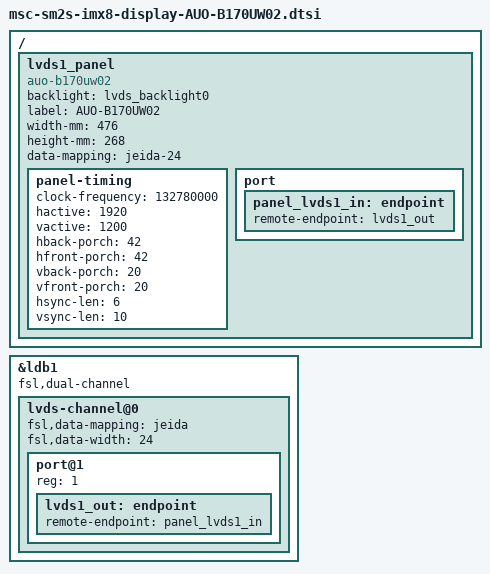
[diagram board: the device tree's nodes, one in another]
/** @file      msc-sm2s-imx8-display-AUO-B170UW02.dtsi

    @copyright Copyright (C) 2021 by MSC Technologies GmbH
    SPDX-License Identifier: GPL-2.0-or-later

    @author    Markus Pietrek

    @details   For single-channel Ampire AUO-B170UW02 connected to LVDS0
			   https://datasheetspdf.com/datasheet/B170UW02-V0.html
*/


/dts-v1/;
/plugin/;

#define LVDS_DISPLAY_0_BACKLIGHT

// chapter 6.5 Power ON/OFF Sequence, page 22 https://datasheetspdf.com/datasheet/B170UW02-V0.html
#define LVDS_BACKLIGHT_POST_PWM_ON_DELAY_MS 200 // T5
#define LVDS_BACKLIGHT_PWM_OFF_DELAY_MS 200 // T6+T3

#include "msc-sm2s-imx8-display.dtsi"

/ {
	fragment@2001 {
		target = <&ldb1>;
		__overlay__ {
			fsl,dual-channel;
			status = "okay";
			lvds-channel@0 {
				fsl,data-mapping = "jeida";
				fsl,data-width = <24>;
				status = "okay";
				#address-cells = <1>;
				#size-cells = <0>;
				port@1 {
					reg = <1>;
					lvds1_out: endpoint {
						remote-endpoint = <&panel_lvds1_in>;
					};
				};
			};
		};
	};

	fragment@2002 {
		target-path = "/";
		__overlay__ {
			#address-cells = <1>;
			#size-cells = <0>;
			lvds1_panel {
				compatible = "auo-b170uw02","panel-lvds";
				backlight = <&lvds_backlight0>;

				label = "AUO-B170UW02";
				width-mm = <476>;
				height-mm = <268>;
				data-mapping = "jeida-24";

				panel-timing {
					// from http://destsm3ux05bbct.emea.avnet.com/projects/THIRDPARTY/repos/linux-vanilla/browse/arch/arm/boot/dts/msc-q7-1920x1080-split-lvds.dtsi?at=msc_v5.4.8_develop
					clock-frequency = <132780000>;
					hactive = <1920>;
					vactive = <1200>;
					hback-porch = <42>;
					hfront-porch = <42>;
					vback-porch = <20>;
					vfront-porch = <20>;
					hsync-len = <6>;
					vsync-len = <10>;
				};

				port {
					panel_lvds1_in: endpoint {
						remote-endpoint = <&lvds1_out>;
					};
				};
			};
		};
	};
};
